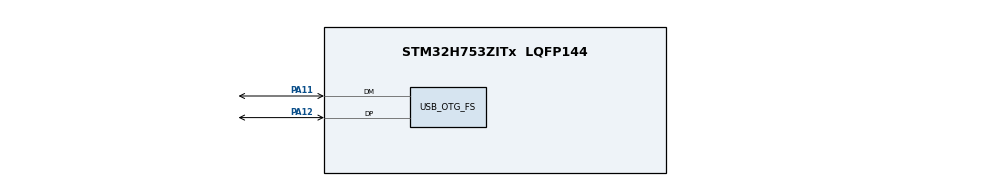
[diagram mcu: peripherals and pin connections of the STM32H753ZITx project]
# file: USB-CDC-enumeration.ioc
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CORTEX_M7.CPU_DCache=Disabled
CORTEX_M7.CPU_ICache=Disabled
CORTEX_M7.MPU_Control=MPU_PRIVILEGED_DEFAULT
CORTEX_M7.default_mode_Activation=1
Mcu.Family=STM32H7
Mcu.Name=STM32H753ZITx
Mcu.Package=LQFP144
NUCLEO-H753ZI.BUTTON=1
NUCLEO-H753ZI.LD1=true
NUCLEO-H753ZI.LD2=true
NUCLEO-H753ZI.LD3=true
NUCLEO-H753ZI.VCP=true
NVIC.EXTI15_10_IRQn=true\:0\:0\:false\:false\:true\:false\:true\:true
NVIC.OTG_FS_IRQn=true\:0\:0\:false\:false\:true\:false\:true\:true
NVIC.PriorityGroup=NVIC_PRIORITYGROUP_4
NVIC.TIM2_IRQn=true\:0\:0\:false\:false\:true\:true\:true\:true
PA11.Mode=Device_Only
PA11.Signal=USB_OTG_FS_DM
PA12.Mode=Device_Only
PA12.Signal=USB_OTG_FS_DP
PC14-OSC32_IN\ (OSC32_IN).Signal=RCC_OSC32_IN
PC15-OSC32_OUT\ (OSC32_OUT).Signal=RCC_OSC32_OUT
PD8.Signal=USART3_TX
PD9.Signal=USART3_RX
PH0-OSC_IN\ (PH0).Signal=RCC_OSC_IN
PH1-OSC_OUT\ (PH1).Signal=RCC_OSC_OUT
ProjectManager.HeapSize=0x200
ProjectManager.StackSize=0x400
ProjectManager.TargetToolchain=CMake
RCC.ADCFreq_Value=129000000
RCC.APB1Freq_Value=64000000
RCC.APB2Freq_Value=64000000
RCC.APB3Freq_Value=64000000
RCC.APB4Freq_Value=64000000
RCC.CortexFreq_Value=64000000
RCC.DIVM1=1
RCC.DIVN1=24
RCC.DIVQ1=4
RCC.HCLKFreq_Value=64000000
RCC.HSE_VALUE=8000000
RCC.PLLFRACN=0
RCC.PWR_Regulator_Voltage_Scale=PWR_REGULATOR_VOLTAGE_SCALE2
RCC.SYSCLKFreq_VALUE=64000000
RCC.USBCLockSelection=RCC_USBCLKSOURCE_HSI48
RCC.USBFreq_Value=48000000
TIM2.AutoReloadPreload=TIM_AUTORELOAD_PRELOAD_ENABLE
TIM2.Period=99
TIM2.Prescaler=63
USB_DEVICE.CLASS_NAME_FS=CDC
USB_DEVICE.VirtualMode-CDC_FS=Cdc
USB_DEVICE.VirtualModeFS=Cdc_FS
USB_OTG_FS.VirtualMode=Device_Only
VP_MEMORYMAP_VS_MEMORYMAP.Mode=CurAppReg
VP_NUCLEO-H753ZI_VS_BSP_COMMON.Mode=COMMON
VP_TIM2_VS_ClockSourceINT.Mode=Internal
VP_USB_DEVICE_VS_USB_DEVICE_CDC_FS.Mode=CDC_FS
board=NUCLEO-H753ZI

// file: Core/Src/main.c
/* USER CODE BEGIN Header */
/**
  ******************************************************************************
  * @file           : main.c
  * @brief          : Main program body
  ******************************************************************************
  * @attention
  *
  * Copyright (c) 2026 STMicroelectronics.
  * All rights reserved.
  *
  * This software is licensed under terms that can be found in the LICENSE file
  * in the root directory of this software component.
  * If no LICENSE file comes with this software, it is provided AS-IS.
  *
  ******************************************************************************
  */
/* USER CODE END Header */
#include "main.h"
#include "usb_device.h"

/* USER CODE BEGIN Includes */
// Standard libraries for memory and string operations
#include "usbd_cdc_if.h"
#include <string.h>
#include <stdio.h>
#include <stdbool.h>

/* USER CODE END Includes */

COM_InitTypeDef BspCOMInit;

TIM_HandleTypeDef htim2;

/* USER CODE BEGIN PV */
typedef enum
{
    STOPPED = 0,
    RUNNING,
    WAITING_FOR_USB
} AcquisitionState;
volatile AcquisitionState acquisition_state = STOPPED;
/* USER CODE END PV */

void SystemClock_Config(void);
static void MPU_Config(void);
static void MX_GPIO_Init(void);
static void MX_TIM2_Init(void);

/* USER CODE BEGIN 0 */
#define CHANNEL_COUNT 16
#define FRAMES_PER_PACKET 16
#define PACKET_SIZE (8 + FRAMES_PER_PACKET * CHANNEL_COUNT * 2)

static uint8_t usb_packet[PACKET_SIZE];
static uint32_t sequence = 0;

#define RING_CAPACITY 256

typedef struct
{
    uint32_t frame_index;
    uint16_t channels[CHANNEL_COUNT];
} SampleFrame;

static SampleFrame ring_buffer[RING_CAPACITY];

static volatile uint32_t write_index = 0;
static volatile uint32_t read_index = 0;
static volatile uint32_t buffered_frames = 0;
// diagnostic counters
static volatile uint32_t overrun_count = 0;
static volatile uint32_t discontinuous_batches = 0;
static volatile uint32_t usb_busy_count = 0;

static SampleFrame usb_batch[FRAMES_PER_PACKET];
static uint32_t next_frame_index = 0;

static void write_u16_le(uint8_t *destination, uint16_t value)
{
    destination[0] = (uint8_t)value;
    destination[1] = (uint8_t)(value >> 8);
}

static void write_u32_le(uint8_t *destination, uint32_t value)
{
    destination[0] = (uint8_t)value;
    destination[1] = (uint8_t)(value >> 8);
    destination[2] = (uint8_t)(value >> 16);
    destination[3] = (uint8_t)(value >> 24);
}
static void build_packet(const SampleFrame *frames)
{
    write_u32_le(&usb_packet[0], 0xA55A5AA5);

    // Index of the first frame in this batch
    write_u32_le(&usb_packet[4], frames[0].frame_index);

    for (int frame = 0; frame < FRAMES_PER_PACKET; frame++)
    {
        for (int ch = 0; ch < CHANNEL_COUNT; ch++)
        {
            int offset = 8 + (frame * CHANNEL_COUNT + ch) * 2;

            write_u16_le(
                &usb_packet[offset],
                frames[frame].channels[ch]
            );
        }
    }
}

static bool push_frame(const SampleFrame *frame)
{
    if (buffered_frames == RING_CAPACITY)
    {
        overrun_count++;
        return false;
    }

    ring_buffer[write_index] = *frame;

    write_index = (write_index + 1) % RING_CAPACITY;
    buffered_frames++;

    return true;
}

static bool pop_frame(SampleFrame *frame)
{
    if (buffered_frames == 0)
    {
        return false;
    }

    *frame = ring_buffer[read_index];

    read_index = (read_index + 1) % RING_CAPACITY;
    buffered_frames--;

    return true;
}

static void generate_frame(void)
{
    SampleFrame frame;

    frame.frame_index = next_frame_index++;

    for (int ch = 0; ch < CHANNEL_COUNT; ch++)
    {
        frame.channels[ch] = (uint16_t)(
            1000 + ch * 100 + (frame.frame_index % 100)
        );
    }

    push_frame(&frame);
}
static volatile uint32_t timer_callback_count = 0;

/* USER CODE END 0 */

int main(void)
{

  /* MPU Configuration--------------------------------------------------------*/
  MPU_Config();

  /* MCU Configuration--------------------------------------------------------*/

  /* Reset of all peripherals, Initializes the Flash interface and the Systick. */
  HAL_Init();

  /* Configure the system clock */
  SystemClock_Config();

  /* Initialize all configured peripherals */
  MX_GPIO_Init();
  MX_USB_DEVICE_Init();
  MX_TIM2_Init();
  /* USER CODE BEGIN 2 */
  /* Acquisition starts only after a host START command. */

  /* USER CODE END 2 */

  /* Initialize leds */
  BSP_LED_Init(LED_GREEN);
  BSP_LED_Init(LED_YELLOW);
  BSP_LED_Init(LED_RED);

  /* Initialize USER push-button, will be used to trigger an interrupt each time it's pressed.*/
  BSP_PB_Init(BUTTON_USER, BUTTON_MODE_EXTI);

  /* Initialize COM1 port (115200, 8 bits (7-bit data + 1 stop bit), no parity */
  BspCOMInit.BaudRate   = 115200;
  BspCOMInit.WordLength = COM_WORDLENGTH_8B;
  BspCOMInit.StopBits   = COM_STOPBITS_1;
  BspCOMInit.Parity     = COM_PARITY_NONE;
  BspCOMInit.HwFlowCtl  = COM_HWCONTROL_NONE;
  if (BSP_COM_Init(COM1, &BspCOMInit) != BSP_ERROR_NONE)
  {
    Error_Handler();
  }

  /* Infinite loop */
  /* USER CODE BEGIN WHILE */
  static bool packet_pending = false;

while (1)
{
    /* Only main changes acquisition state. Keep command consumption and timer
       transitions atomic against USB/TIM2 interrupts. No buffer memset needed. */
    uint32_t control_primask = __get_PRIMASK();
    __disable_irq();
    AcquisitionCommand command = acquisition_command;
    acquisition_command = ACQ_COMMAND_NONE;
    if (command != ACQ_COMMAND_NONE ||
        (!usb_cdc_connected && acquisition_state != STOPPED))
    {
        /* Stop first, including for START while already running. */
        if (HAL_TIM_Base_Stop_IT(&htim2) != HAL_OK)
        {
            Error_Handler();
        }
        acquisition_state = STOPPED;
        __HAL_TIM_CLEAR_FLAG(&htim2, TIM_FLAG_UPDATE);
        HAL_NVIC_ClearPendingIRQ(TIM2_IRQn);
        packet_pending = false;
        write_index = 0;
        read_index = 0;
        buffered_frames = 0;
        if (command == ACQ_COMMAND_START && usb_cdc_connected)
        {
            acquisition_state = WAITING_FOR_USB;
        }
    }
    if (acquisition_state == WAITING_FOR_USB && usb_tx_complete)
    {
        /* Prior transfer completed or endpoints were closed by USB teardown.
           Never clear/rebuild usb_packet while USB still owns it. */
        next_frame_index = 0;
        sequence = 0;
        overrun_count = 0;
        discontinuous_batches = 0;
        usb_busy_count = 0;
        timer_callback_count = 0;
        __HAL_TIM_SET_COUNTER(&htim2, 0);
        __HAL_TIM_CLEAR_FLAG(&htim2, TIM_FLAG_UPDATE);
        HAL_NVIC_ClearPendingIRQ(TIM2_IRQn);
        acquisition_state = RUNNING;
        if (HAL_TIM_Base_Start_IT(&htim2) != HAL_OK)
        {
            Error_Handler();
        }
    }
    __set_PRIMASK(control_primask);

    // Assemble 16 frames when USB is ready
    if (acquisition_state == RUNNING && !packet_pending && usb_tx_complete)
    {
        uint32_t primask = __get_PRIMASK();
        __disable_irq();

        if (buffered_frames >= FRAMES_PER_PACKET)
        {
            for (int i = 0; i < FRAMES_PER_PACKET; i++)
            {
                pop_frame(&usb_batch[i]);
            }

            packet_pending = true;
        }

        __set_PRIMASK(primask);

        if (packet_pending)
        {
            for (int i = 1; i < FRAMES_PER_PACKET; i++)
            {
                if (usb_batch[i].frame_index !=
                    usb_batch[i - 1].frame_index + 1)
                {
                    discontinuous_batches++;
                }
            }

            build_packet(usb_batch);
        }
    }

    // Submit the assembled packet
    uint32_t transmit_primask = __get_PRIMASK();
    __disable_irq();
    if (acquisition_state == RUNNING && packet_pending && usb_tx_complete &&
        acquisition_command == ACQ_COMMAND_NONE && usb_cdc_connected)
    {
        usb_tx_complete = 0;

        if (CDC_Transmit_FS(usb_packet, PACKET_SIZE) == USBD_OK)
        {
            packet_pending = false;
        }
        else
        {
            // Retain the same packet for retry
            usb_busy_count++;
            usb_tx_complete = 1;
        }
    }

    __set_PRIMASK(transmit_primask);

    /* USER CODE END WHILE */

  }
}

void SystemClock_Config(void)
{
  RCC_OscInitTypeDef RCC_OscInitStruct = {0};
  RCC_ClkInitTypeDef RCC_ClkInitStruct = {0};

  /** Supply configuration update enable
  */
  HAL_PWREx_ConfigSupply(PWR_LDO_SUPPLY);

  /** Configure the main internal regulator output voltage
  */
  __HAL_PWR_VOLTAGESCALING_CONFIG(PWR_REGULATOR_VOLTAGE_SCALE2);

  while(!__HAL_PWR_GET_FLAG(PWR_FLAG_VOSRDY)) {}

  /** Initializes the RCC Oscillators according to the specified parameters
  * in the RCC_OscInitTypeDef structure.
  */
  RCC_OscInitStruct.OscillatorType = RCC_OSCILLATORTYPE_HSI48|RCC_OSCILLATORTYPE_HSI;
  RCC_OscInitStruct.HSIState = RCC_HSI_DIV1;
  RCC_OscInitStruct.HSICalibrationValue = RCC_HSICALIBRATION_DEFAULT;
  RCC_OscInitStruct.HSI48State = RCC_HSI48_ON;
  RCC_OscInitStruct.PLL.PLLState = RCC_PLL_NONE;
  if (HAL_RCC_OscConfig(&RCC_OscInitStruct) != HAL_OK)
  {
    Error_Handler();
  }

  /** Initializes the CPU, AHB and APB buses clocks
  */
  RCC_ClkInitStruct.ClockType = RCC_CLOCKTYPE_HCLK|RCC_CLOCKTYPE_SYSCLK
                              |RCC_CLOCKTYPE_PCLK1|RCC_CLOCKTYPE_PCLK2
                              |RCC_CLOCKTYPE_D3PCLK1|RCC_CLOCKTYPE_D1PCLK1;
  RCC_ClkInitStruct.SYSCLKSource = RCC_SYSCLKSOURCE_HSI;
  RCC_ClkInitStruct.SYSCLKDivider = RCC_SYSCLK_DIV1;
  RCC_ClkInitStruct.AHBCLKDivider = RCC_HCLK_DIV1;
  RCC_ClkInitStruct.APB3CLKDivider = RCC_APB3_DIV1;
  RCC_ClkInitStruct.APB1CLKDivider = RCC_APB1_DIV1;
  RCC_ClkInitStruct.APB2CLKDivider = RCC_APB2_DIV1;
  RCC_ClkInitStruct.APB4CLKDivider = RCC_APB4_DIV1;

  if (HAL_RCC_ClockConfig(&RCC_ClkInitStruct, FLASH_LATENCY_1) != HAL_OK)
  {
    Error_Handler();
  }
}

static void MX_TIM2_Init(void)
{

  TIM_ClockConfigTypeDef sClockSourceConfig = {0};
  TIM_MasterConfigTypeDef sMasterConfig = {0};

  htim2.Instance = TIM2;
  htim2.Init.Prescaler = 63;
  htim2.Init.CounterMode = TIM_COUNTERMODE_UP;
  htim2.Init.Period = 99;
  htim2.Init.ClockDivision = TIM_CLOCKDIVISION_DIV1;
  htim2.Init.AutoReloadPreload = TIM_AUTORELOAD_PRELOAD_ENABLE;
  if (HAL_TIM_Base_Init(&htim2) != HAL_OK)
  {
    Error_Handler();
  }
  sClockSourceConfig.ClockSource = TIM_CLOCKSOURCE_INTERNAL;
  if (HAL_TIM_ConfigClockSource(&htim2, &sClockSourceConfig) != HAL_OK)
  {
    Error_Handler();
  }
  sMasterConfig.MasterOutputTrigger = TIM_TRGO_RESET;
  sMasterConfig.MasterSlaveMode = TIM_MASTERSLAVEMODE_DISABLE;
  if (HAL_TIMEx_MasterConfigSynchronization(&htim2, &sMasterConfig) != HAL_OK)
  {
    Error_Handler();
  }

}

static void MX_GPIO_Init(void)
{

  /* GPIO Ports Clock Enable */
  __HAL_RCC_GPIOC_CLK_ENABLE();
  __HAL_RCC_GPIOH_CLK_ENABLE();
  __HAL_RCC_GPIOA_CLK_ENABLE();

}

/* USER CODE BEGIN 4 */
void HAL_TIM_PeriodElapsedCallback(TIM_HandleTypeDef *htim)
{
    if (htim->Instance == TIM2 && acquisition_state == RUNNING)
    {
      timer_callback_count++;
      generate_frame();
    }
}

/* USER CODE END 4 */

 /* MPU Configuration */

void MPU_Config(void)
{
  MPU_Region_InitTypeDef MPU_InitStruct = {0};

  /* Disables the MPU */
  HAL_MPU_Disable();

  /** Initializes and configures the Region and the memory to be protected
  */
  MPU_InitStruct.Enable = MPU_REGION_ENABLE;
  MPU_InitStruct.Number = MPU_REGION_NUMBER0;
  MPU_InitStruct.BaseAddress = 0x0;
  MPU_InitStruct.Size = MPU_REGION_SIZE_4GB;
  MPU_InitStruct.SubRegionDisable = 0x87;
  MPU_InitStruct.TypeExtField = MPU_TEX_LEVEL0;
  MPU_InitStruct.AccessPermission = MPU_REGION_NO_ACCESS;
  MPU_InitStruct.DisableExec = MPU_INSTRUCTION_ACCESS_DISABLE;
  MPU_InitStruct.IsShareable = MPU_ACCESS_SHAREABLE;
  MPU_InitStruct.IsCacheable = MPU_ACCESS_NOT_CACHEABLE;
  MPU_InitStruct.IsBufferable = MPU_ACCESS_NOT_BUFFERABLE;

  HAL_MPU_ConfigRegion(&MPU_InitStruct);
  /* Enables the MPU */
  HAL_MPU_Enable(MPU_PRIVILEGED_DEFAULT);

}

void Error_Handler(void)
{
  __disable_irq();
  while (1)
  {
  }
}
